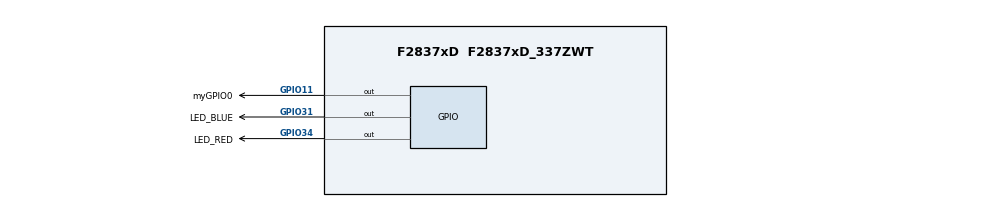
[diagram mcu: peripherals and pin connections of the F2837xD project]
/**
 * @cliArgs --device "F2837xD" --package "F2837xD_337ZWT" --part "F2837xD_337ZWT" --context "CPU1" --product "C2000WARE@4.02.00.00"
 * @versions {"tool":"1.12.0+2406"}
 */

/**
 * Import the modules used in this configuration.
 */
const gpio  = scripting.addModule("/driverlib/gpio.js", {}, false);
const gpio1 = gpio.addInstance();
const gpio2 = gpio.addInstance();
const gpio3 = gpio.addInstance();

/**
 * Write custom configuration values to the imported modules.
 */
gpio1.$name           = "myGPIO0";
gpio1.direction       = "GPIO_DIR_MODE_OUT";
gpio1.gpioPin.$assign = "GPIO11";

gpio2.$name           = "LED_BLUE";
gpio2.direction       = "GPIO_DIR_MODE_OUT";
gpio2.gpioPin.$assign = "GPIO31";

gpio3.$name           = "LED_RED";
gpio3.direction       = "GPIO_DIR_MODE_OUT";
gpio3.gpioPin.$assign = "GPIO34";
